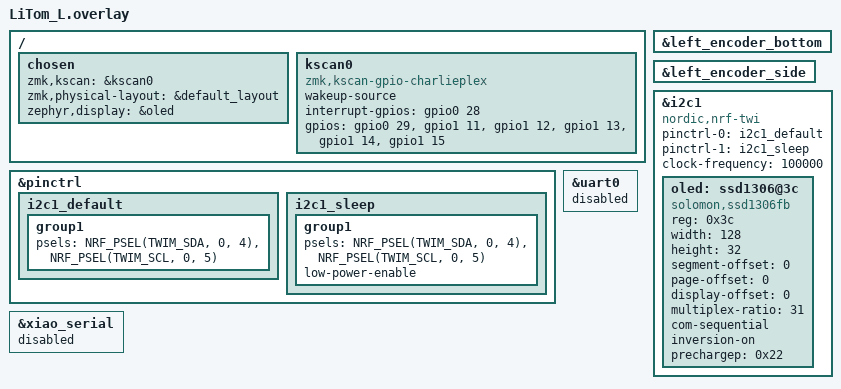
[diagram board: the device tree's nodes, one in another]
#include <dt-bindings/zmk/matrix_transform.h>
#include <physical_layouts.dtsi>
#include "LiTom.dtsi"

/ {
    chosen {
        zmk,kscan = &kscan0;
        zmk,physical-layout = &default_layout;
        zephyr,display = &oled;
    };

    kscan0: kscan0 {
        compatible = "zmk,kscan-gpio-charlieplex";
        // ディープスリープからの復帰口。これが無いと zmk_pm_suspend_devices() が
        // kscan も停止させてしまい (割り込み無効化 + ピン切断)、起こす手段が無くなる。
        wakeup-source;
        interrupt-gpios = <&gpio0 28 (GPIO_ACTIVE_HIGH | GPIO_PULL_DOWN)>;
        gpios
            = <&gpio0 29 GPIO_ACTIVE_HIGH>
            , <&gpio1 11 GPIO_ACTIVE_HIGH>
            , <&gpio1 12 GPIO_ACTIVE_HIGH>
            , <&gpio1 13 GPIO_ACTIVE_HIGH>
            , <&gpio1 14 GPIO_ACTIVE_HIGH>
            , <&gpio1 15 GPIO_ACTIVE_HIGH>
            ;
    };

};

&left_encoder_bottom {
    status = "okay";
};

&left_encoder_side {
    status = "okay";
};

// I2C設定 (OLED用)
&pinctrl {
    i2c1_default: i2c1_default {
        group1 {
            psels = <NRF_PSEL(TWIM_SDA, 0, 4)>,
                    <NRF_PSEL(TWIM_SCL, 0, 5)>;
        };
    };

    i2c1_sleep: i2c1_sleep {
        group1 {
            psels = <NRF_PSEL(TWIM_SDA, 0, 4)>,
                    <NRF_PSEL(TWIM_SCL, 0, 5)>;
            low-power-enable;
        };
    };
};

&i2c1 {
    status = "okay";
    compatible = "nordic,nrf-twi";
    pinctrl-0 = <&i2c1_default>;
    pinctrl-1 = <&i2c1_sleep>;
    pinctrl-names = "default", "sleep";

    clock-frequency = <100000>;
    oled: ssd1306@3c {
        compatible = "solomon,ssd1306fb";
        reg = <0x3c>;
        width = <128>;
        height = <32>;
        segment-offset = <0>;
        page-offset = <0>;
        display-offset = <0>;
        multiplex-ratio = <31>;
        com-sequential;
        inversion-on;
        prechargep = <0x22>;
    };
};

&xiao_serial { status = "disabled"; };
&uart0 { status = "disabled";};
